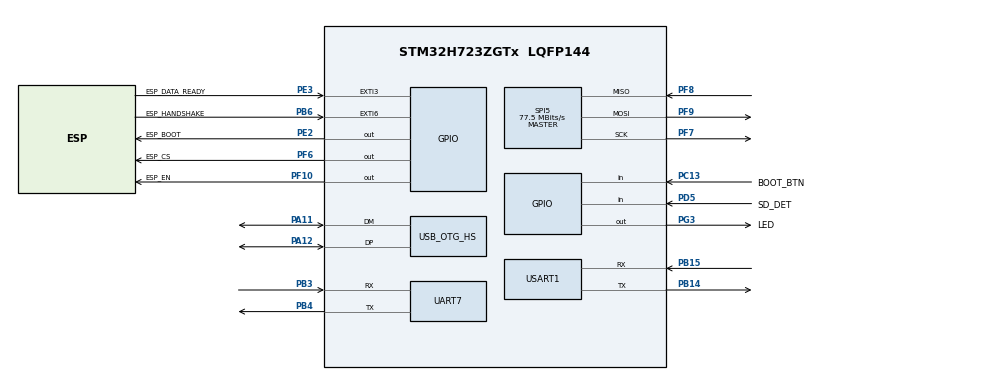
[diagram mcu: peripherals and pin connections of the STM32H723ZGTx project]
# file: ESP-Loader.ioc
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CORTEX_M7.AccessPermission_S-Cortex_Memory_Protection_Unit_Region1_Settings_S=MPU_REGION_FULL_ACCESS
CORTEX_M7.AccessPermission_S-Cortex_Memory_Protection_Unit_Region2_Settings_S=MPU_REGION_FULL_ACCESS
CORTEX_M7.AccessPermission_S-Cortex_Memory_Protection_Unit_Region3_Settings_S=MPU_REGION_PRIV_RW_URO
CORTEX_M7.AccessPermission_S-Cortex_Memory_Protection_Unit_Region4_Settings_S=MPU_REGION_FULL_ACCESS
CORTEX_M7.AccessPermission_S-Cortex_Memory_Protection_Unit_Region5_Settings_S=MPU_REGION_FULL_ACCESS
CORTEX_M7.BaseAddress_S-Cortex_Memory_Protection_Unit_Region1_Settings_S=0x30000000
CORTEX_M7.BaseAddress_S-Cortex_Memory_Protection_Unit_Region2_Settings_S=0x30000000
CORTEX_M7.BaseAddress_S-Cortex_Memory_Protection_Unit_Region3_Settings_S=0x24000000
CORTEX_M7.BaseAddress_S-Cortex_Memory_Protection_Unit_Region4_Settings_S=0xC0000000
CORTEX_M7.BaseAddress_S-Cortex_Memory_Protection_Unit_Region5_Settings_S=0x20000000
CORTEX_M7.CPU_DCache=Enabled
CORTEX_M7.CPU_ICache=Enabled
CORTEX_M7.Enable_S-Cortex_Memory_Protection_Unit_Region1_Settings_S=MPU_REGION_ENABLE
CORTEX_M7.Enable_S-Cortex_Memory_Protection_Unit_Region2_Settings_S=MPU_REGION_ENABLE
CORTEX_M7.Enable_S-Cortex_Memory_Protection_Unit_Region3_Settings_S=MPU_REGION_ENABLE
CORTEX_M7.Enable_S-Cortex_Memory_Protection_Unit_Region4_Settings_S=MPU_REGION_ENABLE
CORTEX_M7.Enable_S-Cortex_Memory_Protection_Unit_Region5_Settings_S=MPU_REGION_ENABLE
CORTEX_M7.IsBufferable_S-Cortex_Memory_Protection_Unit_Region2_Settings_S=MPU_ACCESS_BUFFERABLE
CORTEX_M7.IsBufferable_S-Cortex_Memory_Protection_Unit_Region3_Settings_S=MPU_ACCESS_BUFFERABLE
CORTEX_M7.IsBufferable_S-Cortex_Memory_Protection_Unit_Region4_Settings_S=MPU_ACCESS_BUFFERABLE
CORTEX_M7.IsBufferable_S-Cortex_Memory_Protection_Unit_Region5_Settings_S=MPU_ACCESS_BUFFERABLE
CORTEX_M7.IsCacheable_S-Cortex_Memory_Protection_Unit_Region3_Settings_S=MPU_ACCESS_CACHEABLE
CORTEX_M7.IsCacheable_S-Cortex_Memory_Protection_Unit_Region4_Settings_S=MPU_ACCESS_CACHEABLE
CORTEX_M7.IsCacheable_S-Cortex_Memory_Protection_Unit_Region5_Settings_S=MPU_ACCESS_CACHEABLE
CORTEX_M7.IsShareable_S-Cortex_Memory_Protection_Unit_Region2_Settings_S=MPU_ACCESS_SHAREABLE
CORTEX_M7.IsShareable_S-Cortex_Memory_Protection_Unit_Region3_Settings_S=MPU_ACCESS_SHAREABLE
CORTEX_M7.IsShareable_S-Cortex_Memory_Protection_Unit_Region4_Settings_S=MPU_ACCESS_SHAREABLE
CORTEX_M7.IsShareable_S-Cortex_Memory_Protection_Unit_Region5_Settings_S=MPU_ACCESS_SHAREABLE
CORTEX_M7.IsShareable_Spec=MPU_ACCESS_NOT_SHAREABLE
CORTEX_M7.MPU_Control=__NULL
CORTEX_M7.Size_S-Cortex_Memory_Protection_Unit_Region1_Settings_S=MPU_REGION_SIZE_32KB
CORTEX_M7.Size_S-Cortex_Memory_Protection_Unit_Region2_Settings_S=MPU_REGION_SIZE_512B
CORTEX_M7.Size_S-Cortex_Memory_Protection_Unit_Region3_Settings_S=MPU_REGION_SIZE_512KB
CORTEX_M7.Size_S-Cortex_Memory_Protection_Unit_Region4_Settings_S=MPU_REGION_SIZE_32MB
CORTEX_M7.Size_S-Cortex_Memory_Protection_Unit_Region5_Settings_S=MPU_REGION_SIZE_128KB
CORTEX_M7.TypeExtField_S-Cortex_Memory_Protection_Unit_Region1_Settings_S=MPU_TEX_LEVEL1
CORTEX_M7.default_mode_Activation=1
FREERTOS.Tasks01=defaultTask,24,128,StartDefaultTask,Default,NULL,Dynamic,NULL,NULL
FREERTOS.configUSE_IDLE_HOOK=1
FREERTOS.configUSE_TICK_HOOK=1
Mcu.Family=STM32H7
Mcu.Name=STM32H723ZGTx
Mcu.Package=LQFP144
NVIC.OTG_HS_EP1_IN_IRQn=true\:5\:0\:true\:false\:true\:true\:true\:true\:true
NVIC.OTG_HS_EP1_OUT_IRQn=true\:5\:0\:true\:false\:true\:true\:true\:true\:true
NVIC.OTG_HS_IRQn=true\:5\:0\:true\:false\:true\:true\:true\:true\:true
NVIC.PriorityGroup=NVIC_PRIORITYGROUP_4
NVIC.TIM7_IRQn=true\:15\:0\:false\:false\:true\:false\:false\:true\:true
NVIC.TimeBase=TIM7_IRQn
NVIC.TimeBaseIP=TIM7
NVIC.UART7_IRQn=true\:5\:0\:true\:false\:true\:true\:true\:true\:true
NVIC.USART1_IRQn=true\:5\:0\:true\:false\:true\:true\:true\:true\:true
PA11.Mode=Device_Only_FS
PA11.Signal=USB_OTG_HS_DM
PA12.Mode=Device_Only_FS
PA12.Signal=USB_OTG_HS_DP
PA13(JTMS/SWDIO).Mode=Serial_Wire
PA13(JTMS/SWDIO).Signal=DEBUG_JTMS-SWDIO
PA14(JTCK/SWCLK).Mode=Serial_Wire
PA14(JTCK/SWCLK).Signal=DEBUG_JTCK-SWCLK
PB14.Mode=Asynchronous
PB14.Signal=USART1_TX
PB15.Mode=Asynchronous
PB15.Signal=USART1_RX
PB3(JTDO/TRACESWO).Mode=Asynchronous
PB3(JTDO/TRACESWO).Signal=UART7_RX
PB4(NJTRST).Mode=Asynchronous
PB4(NJTRST).Signal=UART7_TX
PB6.GPIO_Label=ESP_HANDSHAKE
PB6.Signal=GPXTI6
PC0.Signal=FMC_SDNWE
PC13.GPIO_Label=BOOT_BTN
PC13.Signal=GPIO_Input
PC14-OSC32_IN.Mode=LSE-External-Oscillator
PC14-OSC32_IN.Signal=RCC_OSC32_IN
PC15-OSC32_OUT.Mode=LSE-External-Oscillator
PC15-OSC32_OUT.Signal=RCC_OSC32_OUT
PC2_C.Signal=FMC_SDNE0
PC3_C.Signal=FMC_SDCKE0
PD0.Signal=FMC_D2_DA2
PD1.Signal=FMC_D3_DA3
PD10.Signal=FMC_D15_DA15
PD14.Signal=FMC_D0_DA0
PD15.Signal=FMC_D1_DA1
PD5.GPIO_Label=SD_DET
PD5.Signal=GPIO_Input
PD6.Signal=SDMMC2_CK
PD7.Signal=SDMMC2_CMD
PD8.Signal=FMC_D13_DA13
PD9.Signal=FMC_D14_DA14
PE0.Signal=FMC_NBL0
PE1.Signal=FMC_NBL1
PE10.Signal=FMC_D7_DA7
PE11.Signal=FMC_D8_DA8
PE12.Signal=FMC_D9_DA9
PE13.Signal=FMC_D10_DA10
PE14.Signal=FMC_D11_DA11
PE15.Signal=FMC_D12_DA12
PE2.GPIO_Label=ESP_BOOT
PE2.GPIO_ModeDefaultOutputPP=GPIO_MODE_OUTPUT_PP
PE2.GPIO_PuPd=GPIO_NOPULL
PE2.GPIO_Speed=GPIO_SPEED_FREQ_VERY_HIGH
PE2.PinState=GPIO_PIN_RESET
PE2.Signal=GPIO_Output
PE3.GPIO_Label=ESP_DATA_READY
PE3.Signal=GPXTI3
PE7.Signal=FMC_D4_DA4
PE8.Signal=FMC_D5_DA5
PE9.Signal=FMC_D6_DA6
PF0.Signal=FMC_A0
PF1.Signal=FMC_A1
PF10.GPIO_Label=ESP_EN
PF10.GPIO_Speed=GPIO_SPEED_FREQ_VERY_HIGH
PF10.Signal=GPIO_Output
PF11.Signal=FMC_SDNRAS
PF12.Signal=FMC_A6
PF13.Signal=FMC_A7
PF14.Signal=FMC_A8
PF15.Signal=FMC_A9
PF2.Signal=FMC_A2
PF3.Signal=FMC_A3
PF4.Signal=FMC_A4
PF5.Signal=FMC_A5
PF6.GPIO_Label=ESP_CS
PF6.Signal=GPIO_Output
PF7.Mode=Full_Duplex_Master
PF7.Signal=SPI5_SCK
PF8.Mode=Full_Duplex_Master
PF8.Signal=SPI5_MISO
PF9.Mode=Full_Duplex_Master
PF9.Signal=SPI5_MOSI
PG0.Signal=FMC_A10
PG1.Signal=FMC_A11
PG10.Signal=SDMMC2_D1
PG11.Signal=SDMMC2_D2
PG12.Signal=SDMMC2_D3
PG15.Signal=FMC_SDNCAS
PG2.Signal=FMC_A12
PG3.GPIO_Label=LED
PG3.Signal=GPIO_Output
PG4.Signal=FMC_A14_BA0
PG5.Signal=FMC_A15_BA1
PG8.Signal=FMC_SDCLK
PG9.Signal=SDMMC2_D0
PH0-OSC_IN.Mode=HSE-External-Oscillator
PH0-OSC_IN.Signal=RCC_OSC_IN
PH1-OSC_OUT.Mode=HSE-External-Oscillator
PH1-OSC_OUT.Signal=RCC_OSC_OUT
ProjectManager.HeapSize=0x200
ProjectManager.StackSize=0x400
ProjectManager.TargetToolchain=CMake
RCC.ADCCLockSelection=RCC_ADCCLKSOURCE_CLKP
RCC.ADCFreq_Value=64000000
RCC.APB1Freq_Value=137500000
RCC.APB2Freq_Value=137500000
RCC.APB3Freq_Value=137500000
RCC.APB4Freq_Value=137500000
RCC.CECCLockSelection=RCC_CECCLKSOURCE_LSI
RCC.CKPERSourceSelection=RCC_CLKPSOURCE_HSI
RCC.CSI_VALUE=4000000
RCC.CortexFreq_Value=550000000
RCC.Cortex_Div=SYSTICK_CLKSOURCE_HCLK
RCC.Cortex_DivARG=SystemCoreClock/1000
RCC.D1CPRE=RCC_SYSCLK_DIV1
RCC.D1PPRE=RCC_APB3_DIV2
RCC.D2PPRE1=RCC_APB1_DIV2
RCC.D2PPRE2=RCC_APB2_DIV2
RCC.D3PPRE=RCC_APB4_DIV2
RCC.DFSDMCLockSelection=RCC_DFSDM1CLKSOURCE_D2PCLK1
RCC.DIVM1=5
RCC.DIVM2=5
RCC.DIVM3=10
RCC.DIVN1=110
RCC.DIVN2=62
RCC.DIVN3=80
RCC.DIVP1=1
RCC.DIVP2=2
RCC.DIVP3=2
RCC.DIVQ1=4
RCC.DIVQ2=2
RCC.DIVQ3=4
RCC.DIVR1=2
RCC.DIVR2=2
RCC.DIVR3=4
RCC.EXTERNAL_CLOCK_VALUE=12288000
RCC.FDCANCLockSelection=RCC_FDCANCLKSOURCE_PLL
RCC.FMCCLockSelection=RCC_FMCCLKSOURCE_D1HCLK
RCC.HCLKFreq_Value=275000000
RCC.HPRE=RCC_HCLK_DIV2
RCC.HSE_VALUE=25000000
RCC.HSI48_VALUE=48000000
RCC.HSIDiv=RCC_PLLSAIDIVR_1
RCC.HSI_VALUE=64000000
RCC.I2C123CLockSelection=RCC_I2C1235CLKSOURCE_D2PCLK1
RCC.I2C4CLockSelection=RCC_I2C4CLKSOURCE_D3PCLK1
RCC.LPTIM1CLockSelection=RCC_LPTIM1CLKSOURCE_D2PCLK1
RCC.LPTIM2CLockSelection=RCC_LPTIM2CLKSOURCE_D3PCLK1
RCC.LPTIM345CLockSelection=RCC_LPTIM345CLKSOURCE_D3PCLK1
RCC.LPUART1CLockSelection=RCC_LPUART1CLKSOURCE_D3PCLK1
RCC.PLL2FRACN=0
RCC.PLL2_VCI_Range-AdvancedSettings=RCC_PLL2VCIRANGE_3
RCC.PLL3FRACN=0
RCC.PLLFRACN=0
RCC.PLLSourceVirtual=RCC_PLLSOURCE_HSE
RCC.QSPICLockSelection=RCC_OSPICLKSOURCE_D1HCLK
RCC.RCC_MCO1Source=RCC_MCO1SOURCE_HSI
RCC.RCC_MCO2Source=RCC_MCO2SOURCE_SYSCLK
RCC.RCC_MCODiv1=RCC_MCODIV_1
RCC.RCC_MCODiv2=RCC_MCODIV_1
RCC.RCC_RTC_Clock_Source_FROM_HSE=RCC_RTCCLKSOURCE_HSE_DIV2
RCC.RNGCLockSelection=RCC_RNGCLKSOURCE_HSI48
RCC.RTCClockSelection=RCC_RTCCLKSOURCE_LSE
RCC.SAI1CLockSelection=RCC_SAI1CLKSOURCE_PLL
RCC.SAI4ACLockSelection=RCC_SAI4ACLKSOURCE_PLL
RCC.SAI4BCLockSelection=RCC_SAI4BCLKSOURCE_PLL
RCC.SPDIFCLockSelection=RCC_SPDIFRXCLKSOURCE_PLL
RCC.SPI123CLockSelection=RCC_SPI123CLKSOURCE_PLL2
RCC.SPI6CLockSelection=RCC_SPI6CLKSOURCE_D3PCLK1
RCC.SWPCLockSelection=RCC_SWPMI1CLKSOURCE_D2PCLK1
RCC.SYSCLKFreq_VALUE=550000000
RCC.SYSCLKSource=RCC_SYSCLKSOURCE_PLLCLK
RCC.Spi45ClockSelection=RCC_SPI45CLKSOURCE_PLL2
RCC.SupplySource=PWR_LDO_SUPPLY
RCC.USART16CLockSelection=RCC_USART16910CLKSOURCE_PLL3
RCC.USART234578CLockSelection=RCC_USART234578CLKSOURCE_PLL3
RCC.USBCLockSelection=RCC_USBCLKSOURCE_HSI48
RCC.USBFreq_Value=48000000
SH.FMC_A0.0=FMC_A0
SH.FMC_A1.0=FMC_A1
SH.FMC_A10.0=FMC_A10
SH.FMC_A11.0=FMC_A11
SH.FMC_A12.0=FMC_A12
SH.FMC_A14_BA0.0=FMC_BA0
SH.FMC_A15_BA1.0=FMC_BA1
SH.FMC_A2.0=FMC_A2
SH.FMC_A3.0=FMC_A3
SH.FMC_A4.0=FMC_A4
SH.FMC_A5.0=FMC_A5
SH.FMC_A6.0=FMC_A6
SH.FMC_A7.0=FMC_A7
SH.FMC_A8.0=FMC_A8
SH.FMC_A9.0=FMC_A9
SH.FMC_D0_DA0.0=FMC_D0
SH.FMC_D10_DA10.0=FMC_D10
SH.FMC_D11_DA11.0=FMC_D11
SH.FMC_D12_DA12.0=FMC_D12
SH.FMC_D13_DA13.0=FMC_D13
SH.FMC_D14_DA14.0=FMC_D14
SH.FMC_D15_DA15.0=FMC_D15
SH.FMC_D1_DA1.0=FMC_D1
SH.FMC_D2_DA2.0=FMC_D2
SH.FMC_D3_DA3.0=FMC_D3
SH.FMC_D4_DA4.0=FMC_D4
SH.FMC_D5_DA5.0=FMC_D5
SH.FMC_D6_DA6.0=FMC_D6
SH.FMC_D7_DA7.0=FMC_D7
SH.FMC_D8_DA8.0=FMC_D8
SH.FMC_D9_DA9.0=FMC_D9
SH.FMC_NBL0.0=FMC_NBL0
SH.FMC_NBL1.0=FMC_NBL1
SH.FMC_SDCLK.0=FMC_SDCLK
SH.FMC_SDNCAS.0=FMC_SDNCAS
SH.FMC_SDNRAS.0=FMC_SDNRAS
SH.FMC_SDNWE.0=FMC_SDNWE
SPI5.BaudRatePrescaler=SPI_BAUDRATEPRESCALER_2
SPI5.CalculateBaudRate=77.5 MBits/s
SPI5.Direction=SPI_DIRECTION_2LINES
SPI5.Mode=SPI_MODE_MASTER
SPI5.VirtualType=VM_MASTER
UART7.DMADisableonRxErrorParam=UART_ADVFEATURE_DMA_DISABLEONRXERROR
UART7.OverSampling=UART_OVERSAMPLING_16
UART7.OverrunDisableParam=UART_ADVFEATURE_OVERRUN_DISABLE
UART7.WordLength=WORDLENGTH_8B
USART1.DMADisableonRxErrorParam=ADVFEATURE_DMA_DISABLEONRXERROR
USART1.OverrunDisableParam=ADVFEATURE_OVERRUN_DISABLE
USART1.VirtualMode-Asynchronous=VM_ASYNC
USB_DEVICE.CLASS_NAME_HS=CDC
USB_DEVICE.VirtualMode=Cdc
USB_DEVICE.VirtualModeHS=Cdc_HS
USB_OTG_HS.VirtualMode-Device_Only_FS=Device_Only_FS
VP_DTS_VS-DTS.Mode=DTS
VP_FREERTOS_VS_CMSIS_V2.Mode=CMSIS_V2
VP_MEMORYMAP_VS_MEMORYMAP.Mode=CurAppReg
VP_RTC_VS_RTC_Activate.Mode=RTC_Enabled
VP_RTC_VS_RTC_Calendar.Mode=RTC_Calendar
VP_SYS_VS_tim7.Mode=TIM7
VP_USB_DEVICE_VS_USB_DEVICE_CDC_HS.Mode=CDC_HS
board=custom

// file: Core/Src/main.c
/* USER CODE BEGIN Header */
/**
  ******************************************************************************
  * @file           : main.c
  * @brief          : Main program body
  ******************************************************************************
  * @attention
  *
  * Copyright (c) 2024 STMicroelectronics.
  * All rights reserved.
  *
  * This software is licensed under terms that can be found in the LICENSE file
  * in the root directory of this software component.
  * If no LICENSE file comes with this software, it is provided AS-IS.
  *
  ******************************************************************************
  */
/* USER CODE END Header */
#include "main.h"
#include "cmsis_os.h"
#include "dts.h"
#include "memorymap.h"
#include "rtc.h"
#include "spi.h"
#include "usart.h"
#include "usb_device.h"
#include "gpio.h"

void SystemClock_Config(void);
void PeriphCommonClock_Config(void);
void MX_FREERTOS_Init(void);

int main(void)
{

  /* Enable the CPU Cache */

  /* Enable I-Cache---------------------------------------------------------*/
  SCB_EnableICache();

  /* Enable D-Cache---------------------------------------------------------*/
  SCB_EnableDCache();

  /* MCU Configuration--------------------------------------------------------*/

  /* Reset of all peripherals, Initializes the Flash interface and the Systick. */
  HAL_Init();

  /* Configure the system clock */
  SystemClock_Config();

  /* Configure the peripherals common clocks */
  PeriphCommonClock_Config();

  /* Initialize all configured peripherals */
  MX_GPIO_Init();
  MX_SPI5_Init();
  MX_UART7_Init();
  MX_USART1_UART_Init();
  MX_DTS_Init();
  MX_RTC_Init();
  /* USER CODE BEGIN 2 */
  #include "usart.h"
  HAL_UART_Transmit(&huart1, (uint8_t*)"Enter bootloader mode\r\n", 28, 100);
  /* USER CODE END 2 */

  /* Init scheduler */
  osKernelInitialize();

  /* Call init function for freertos objects (in cmsis_os2.c) */
  MX_FREERTOS_Init();

  /* Start scheduler */
  osKernelStart();

  /* We should never get here as control is now taken by the scheduler */

  /* Infinite loop */
  while (1)
  {

  }
}

void SystemClock_Config(void)
{
  RCC_OscInitTypeDef RCC_OscInitStruct = {0};
  RCC_ClkInitTypeDef RCC_ClkInitStruct = {0};

  /** Supply configuration update enable
  */
  HAL_PWREx_ConfigSupply(PWR_LDO_SUPPLY);

  /** Configure the main internal regulator output voltage
  */
  __HAL_PWR_VOLTAGESCALING_CONFIG(PWR_REGULATOR_VOLTAGE_SCALE0);

  while(!__HAL_PWR_GET_FLAG(PWR_FLAG_VOSRDY)) {}

  /** Configure LSE Drive Capability
  */
  HAL_PWR_EnableBkUpAccess();
  __HAL_RCC_LSEDRIVE_CONFIG(RCC_LSEDRIVE_LOW);

  /** Initializes the RCC Oscillators according to the specified parameters
  * in the RCC_OscInitTypeDef structure.
  */
  RCC_OscInitStruct.OscillatorType = RCC_OSCILLATORTYPE_HSI48|RCC_OSCILLATORTYPE_HSE
                              |RCC_OSCILLATORTYPE_LSE;
  RCC_OscInitStruct.HSEState = RCC_HSE_ON;
  RCC_OscInitStruct.LSEState = RCC_LSE_ON;
  RCC_OscInitStruct.HSI48State = RCC_HSI48_ON;
  RCC_OscInitStruct.PLL.PLLState = RCC_PLL_ON;
  RCC_OscInitStruct.PLL.PLLSource = RCC_PLLSOURCE_HSE;
  RCC_OscInitStruct.PLL.PLLM = 5;
  RCC_OscInitStruct.PLL.PLLN = 110;
  RCC_OscInitStruct.PLL.PLLP = 1;
  RCC_OscInitStruct.PLL.PLLQ = 4;
  RCC_OscInitStruct.PLL.PLLR = 2;
  RCC_OscInitStruct.PLL.PLLRGE = RCC_PLL1VCIRANGE_2;
  RCC_OscInitStruct.PLL.PLLVCOSEL = RCC_PLL1VCOWIDE;
  RCC_OscInitStruct.PLL.PLLFRACN = 0;
  if (HAL_RCC_OscConfig(&RCC_OscInitStruct) != HAL_OK)
  {
    Error_Handler();
  }

  /** Initializes the CPU, AHB and APB buses clocks
  */
  RCC_ClkInitStruct.ClockType = RCC_CLOCKTYPE_HCLK|RCC_CLOCKTYPE_SYSCLK
                              |RCC_CLOCKTYPE_PCLK1|RCC_CLOCKTYPE_PCLK2
                              |RCC_CLOCKTYPE_D3PCLK1|RCC_CLOCKTYPE_D1PCLK1;
  RCC_ClkInitStruct.SYSCLKSource = RCC_SYSCLKSOURCE_PLLCLK;
  RCC_ClkInitStruct.SYSCLKDivider = RCC_SYSCLK_DIV1;
  RCC_ClkInitStruct.AHBCLKDivider = RCC_HCLK_DIV2;
  RCC_ClkInitStruct.APB3CLKDivider = RCC_APB3_DIV2;
  RCC_ClkInitStruct.APB1CLKDivider = RCC_APB1_DIV2;
  RCC_ClkInitStruct.APB2CLKDivider = RCC_APB2_DIV2;
  RCC_ClkInitStruct.APB4CLKDivider = RCC_APB4_DIV2;

  if (HAL_RCC_ClockConfig(&RCC_ClkInitStruct, FLASH_LATENCY_3) != HAL_OK)
  {
    Error_Handler();
  }
}

void PeriphCommonClock_Config(void)
{
  RCC_PeriphCLKInitTypeDef PeriphClkInitStruct = {0};

  /** Initializes the peripherals clock
  */
  PeriphClkInitStruct.PeriphClockSelection = RCC_PERIPHCLK_USART1|RCC_PERIPHCLK_UART7;
  PeriphClkInitStruct.PLL3.PLL3M = 10;
  PeriphClkInitStruct.PLL3.PLL3N = 80;
  PeriphClkInitStruct.PLL3.PLL3P = 2;
  PeriphClkInitStruct.PLL3.PLL3Q = 4;
  PeriphClkInitStruct.PLL3.PLL3R = 4;
  PeriphClkInitStruct.PLL3.PLL3RGE = RCC_PLL3VCIRANGE_1;
  PeriphClkInitStruct.PLL3.PLL3VCOSEL = RCC_PLL3VCOWIDE;
  PeriphClkInitStruct.PLL3.PLL3FRACN = 0;
  PeriphClkInitStruct.Usart234578ClockSelection = RCC_USART234578CLKSOURCE_PLL3;
  PeriphClkInitStruct.Usart16ClockSelection = RCC_USART16910CLKSOURCE_PLL3;
  if (HAL_RCCEx_PeriphCLKConfig(&PeriphClkInitStruct) != HAL_OK)
  {
    Error_Handler();
  }
}

void HAL_TIM_PeriodElapsedCallback(TIM_HandleTypeDef *htim)
{
  if (htim->Instance == TIM7)
  {
    HAL_IncTick();
  }
}

void Error_Handler(void)
{
  __disable_irq();
  while (1)
  {
  }
}
